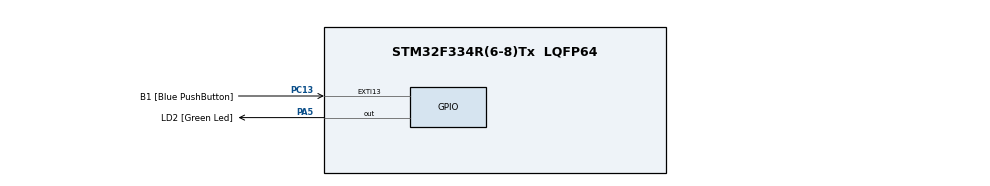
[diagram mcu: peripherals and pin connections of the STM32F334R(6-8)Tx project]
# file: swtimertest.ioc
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Mcu.Family=STM32F3
Mcu.Name=STM32F334R(6-8)Tx
Mcu.Package=LQFP64
Mcu.UserConstants=CLOCKS_PER_USEC,64;T7_COUNTS_PER_MSEC,1000;T3_NS_PER_COUNT,250;T3_COUNTS_PER_USEC,4;T3_MAX_USEC,16384;T3_MAX_MSEC,16;T7_COUNTS_PER_USEC,1;T7_NS_PER_COUNT,1000
NVIC.PriorityGroup=NVIC_PRIORITYGROUP_2
NVIC.TIM3_IRQn=true\:1\:1\:true\:true\:true\:2\:true
NVIC.TIM7_DAC2_IRQn=true\:1\:2\:true\:true\:true\:1\:true
PA13.GPIO_Label=TMS
PA13.Mode=Serial_Wire
PA13.Signal=SYS_JTMS-SWDIO
PA14.GPIO_Label=TCK
PA14.Mode=Serial_Wire
PA14.Signal=SYS_JTCK-SWCLK
PA2.GPIO_Label=USART_TX
PA2.Signal=USART2_TX
PA3.GPIO_Label=USART_RX
PA3.Signal=USART2_RX
PA5.GPIO_Label=LD2 [Green Led]
PA5.Signal=GPIO_Output
PB3.GPIO_Label=SWO
PB3.Signal=SYS_JTDO-TRACESWO
PC13.GPIO_Label=B1 [Blue PushButton]
PC13.GPIO_ModeDefaultEXTI=GPIO_MODE_IT_FALLING
PC13.Signal=GPXTI13
PC14\ /\ OSC32_IN.Signal=RCC_OSC32_IN
PC15\ /\ OSC32_OUT.GPIO_Label=RCC_OSC32_OUT
PC15\ /\ OSC32_OUT.Signal=RCC_OSC32_OUT
PF0\ /\ OSC_IN.Signal=RCC_OSC_IN
PF1\ /\ OSC_OUT.Signal=RCC_OSC_OUT
ProjectManager.HeapSize=0x200
ProjectManager.StackSize=0x1000
ProjectManager.TargetToolchain=MDK-ARM V5
RCC.AHBFreq_Value=64000000
RCC.APB1CLKDivider=RCC_HCLK_DIV2
RCC.APB1Freq_Value=32000000
RCC.APB1TimFreq_Value=64000000
RCC.APB2Freq_Value=64000000
RCC.APB2TimFreq_Value=64000000
RCC.CortexFreq_Value=64000000
RCC.FLatency-AdvancedSettings=FLASH_LATENCY_2
RCC.HCLKFreq_Value=64000000
RCC.HSE_VALUE=8000000
RCC.HSI_VALUE=8000000
RCC.LSE_VALUE=32768
RCC.PLLMUL=RCC_PLL_MUL16
RCC.SYSCLKFreq_VALUE=64000000
RCC.SYSCLKSourceVirtual=RCC_SYSCLKSOURCE_PLLCLK
TIM3.Channel-Output\ Compare1\ No\ Output=TIM_CHANNEL_1
TIM3.Channel-Output\ Compare2\ No\ Output=TIM_CHANNEL_2
TIM3.Channel-Output\ Compare3\ No\ Output=TIM_CHANNEL_3
TIM3.Channel-Output\ Compare4\ No\ Output=TIM_CHANNEL_4
TIM3.Period=0xffff
TIM3.Prescaler=15
TIM3.TIM_MasterSlaveMode=TIM_MASTERSLAVEMODE_ENABLE
TIM7.Period=65535
TIM7.Prescaler=63
VP_CRC_VS_CRC.Mode=CRC_Activate
VP_TIM3_VS_ClockSourceINT.Mode=Internal
VP_TIM3_VS_no_output1.Mode=Output Compare1 No Output
VP_TIM3_VS_no_output2.Mode=Output Compare2 No Output
VP_TIM3_VS_no_output3.Mode=Output Compare3 No Output
VP_TIM3_VS_no_output4.Mode=Output Compare4 No Output
VP_TIM7_VS_ClockSourceINT.Mode=Enable_Timer
board=NUCLEO-F334R8

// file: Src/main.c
/**
  ******************************************************************************
  * File Name          : main.c
  * Description        : Main program body
  ******************************************************************************
  ** This notice applies to any and all portions of this file
  * that are not between comment pairs USER CODE BEGIN and
  * USER CODE END. Other portions of this file, whether
  * inserted by the user or by software development tools
  * are owned by their respective copyright owners.
  *
  * COPYRIGHT(c) 2018 STMicroelectronics
  *
  * Redistribution and use in source and binary forms, with or without modification,
  * are permitted provided that the following conditions are met:
  *   1. Redistributions of source code must retain the above copyright notice,
  *      this list of conditions and the following disclaimer.
  *   2. Redistributions in binary form must reproduce the above copyright notice,
  *      this list of conditions and the following disclaimer in the documentation
  *      and/or other materials provided with the distribution.
  *   3. Neither the name of STMicroelectronics nor the names of its contributors
  *      may be used to endorse or promote products derived from this software
  *      without specific prior written permission.
  *
  * THIS SOFTWARE IS PROVIDED BY THE COPYRIGHT HOLDERS AND CONTRIBUTORS "AS IS"
  * AND ANY EXPRESS OR IMPLIED WARRANTIES, INCLUDING, BUT NOT LIMITED TO, THE
  * IMPLIED WARRANTIES OF MERCHANTABILITY AND FITNESS FOR A PARTICULAR PURPOSE ARE
  * DISCLAIMED. IN NO EVENT SHALL THE COPYRIGHT HOLDER OR CONTRIBUTORS BE LIABLE
  * FOR ANY DIRECT, INDIRECT, INCIDENTAL, SPECIAL, EXEMPLARY, OR CONSEQUENTIAL
  * DAMAGES (INCLUDING, BUT NOT LIMITED TO, PROCUREMENT OF SUBSTITUTE GOODS OR
  * SERVICES; LOSS OF USE, DATA, OR PROFITS; OR BUSINESS INTERRUPTION) HOWEVER
  * CAUSED AND ON ANY THEORY OF LIABILITY, WHETHER IN CONTRACT, STRICT LIABILITY,
  * OR TORT (INCLUDING NEGLIGENCE OR OTHERWISE) ARISING IN ANY WAY OUT OF THE USE
  * OF THIS SOFTWARE, EVEN IF ADVISED OF THE POSSIBILITY OF SUCH DAMAGE.
  *
  ******************************************************************************
  */
#include "main.h"
#include "stm32f3xx_hal.h"
#include "crc.h"
#include "tim.h"
#include "gpio.h"

/* USER CODE BEGIN Includes */
#include <alloca.h>
#include "taskService.h"
#include "swbgtimers.h"
#include "gencmdef.h"
#include "generalQueue.h"

/* USER CODE END Includes */

/* USER CODE BEGIN PV */
/* Private variables ---------------------------------------------------------*/

/* USER CODE END PV */

void SystemClock_Config(void);
static void MX_NVIC_Init(void);

/* USER CODE BEGIN PFP */
/* Private function prototypes -----------------------------------------------*/

/* USER CODE END PFP */

/* USER CODE BEGIN 0 */
#define NUM_OF_TASKS 10
extern __IO uint32_t uwTick;
__IO uint32_t *someCounter = &uwTick;

uint32_t tasksAllowed;
taskHandle_t bgTimerTask;
taskHandle_t task1Task;
taskHandle_t task2Task;
taskHandle_t task3Task;
taskHandle_t task4Task;
uint32_t GetTimeuSec(void);
uint32_t extendedTick;
uint32_t testusec;
/// The system tick callback
void HAL_SYSTICK_Callback(void)
{
    // Schedule background timer task
    TS_SignalTask(bgTimerTask);
    if (uwTick == 0)extendedTick++;
    testusec = GetTimeuSec();
}

volatile uint32_t Clock3;
volatile uint32_t Clock7;

/// The timer rollover ISR callback
void HAL_TIM_PeriodElapsedCallback(TIM_HandleTypeDef *htim)
{
    if (htim == &htim3) ++Clock3;
    if (htim == &htim7) ++Clock7;
}

uint32_t GetTimeuSec(void)
{
    uint32_t change, time1 = (Clock3<<14)+ ((htim3.Instance->CNT)>>2);
    uint32_t time2;
    do
    {
        time2 = (Clock3<<14)+ ((htim3.Instance->CNT)>>2);
        if (time2 - time1 > 1)
        {
            time1=time2;
            change=1;
        }
        else change = 0;
    }while(change);

    return time2;
}

static void subTask(int cnt)
{
    volatile int i;
    for (i = 0; i < cnt; i++)
    {
        if ( 0 == i%1000 )
        {
            TS_Yield();
        }
    }
}

void task1(void)
{
    subTask(3000);
    TS_SignalTask(task4Task);
    TS_SignalTask(task2Task);
}

void task2(void)
{
    subTask(30000);
    TS_SignalTask(task3Task);
}

void task3(void)
{
    subTask(300000);
    TS_SignalTask(task1Task);
}

void task4(void)
{
    subTask(3000000);
    TS_SignalTask(task2Task);
}

uint32_t futureCalled;

int32_t fut2dif;
void futureTest2(intptr_t startTime)
{
    static int32_t cnt;
    futureCalled++;
    fut2dif = (GetTimeuSec() - startTime) / ++cnt;
}

int32_t fut20dif;
void futureTest20(intptr_t startTime)
{
    static int32_t cnt;
    futureCalled++;
    fut20dif = (GetTimeuSec() - startTime) / ++cnt;
}

int32_t fut200dif;
void futureTest200(intptr_t startTime)
{
    static int32_t cnt;
    futureCalled++;
    fut200dif = (GetTimeuSec() - startTime) / ++cnt;
}

int32_t fut2000dif;
void futureTest2000(intptr_t startTime)
{
    static int32_t cnt;
    futureCalled++;
    fut2000dif = (GetTimeuSec() - startTime) / ++cnt;
}

/* USER CODE END 0 */

int main(void)
{

  /* MCU Configuration----------------------------------------------------------*/

  /* Reset of all peripherals, Initializes the Flash interface and the Systick. */
  HAL_Init();

  /* Configure the system clock */
  SystemClock_Config();

  /* Initialize all configured peripherals */
  MX_GPIO_Init();
  MX_TIM7_Init();
  MX_CRC_Init();
  MX_TIM3_Init();

  /* Initialize interrupts */
  MX_NVIC_Init();

  /* USER CODE BEGIN 2 */

  HAL_ResumeTick();

  HAL_TIM_Base_Start_IT(&htim3);
//  HAL_TIM_Base_Start_IT(&htim6);
  HAL_TIM_Base_Start_IT(&htim7);

  SWT_FastInit();

  // allocate space for the tasks
  uint32_t *space = alloca(TS_InitGetSize(NUM_OF_TASKS));
  tasksAllowed = TS_Init(space,TS_InitGetSize(NUM_OF_TASKS));
  if(tasksAllowed != NUM_OF_TASKS)
    { while (1) {} }  // Oh Crap
  // make the background timer a task itself
  bgTimerTask =  TS_AddTask(SWT_Background);
  task1Task =  TS_AddTask(task1);
  task2Task =  TS_AddTask(task2);
  task3Task =  TS_AddTask(task3);
  task4Task =  TS_AddTask(task4);

  TS_SignalTask(task3Task);

  // launch future test
SWT_FastTimerCallback(futureTest2000, 2000000, 256, GetTimeuSec());
SWT_FastTimerCallback(futureTest200, 200000, 256, GetTimeuSec());
SWT_FastTimerCallback(futureTest20, 20000, 256, GetTimeuSec());
SWT_FastTimerCallback(futureTest2, 2000, 256, GetTimeuSec());

  /* USER CODE END 2 */

  /* Infinite loop */
  /* USER CODE BEGIN WHILE */
  while (1)
  {
    // The task runner
    TS_Background();
  /* USER CODE END WHILE */

  }

}

/** System Clock Configuration
*/
void SystemClock_Config(void)
{

  LL_FLASH_SetLatency(LL_FLASH_LATENCY_2);

   if(LL_FLASH_GetLatency() != LL_FLASH_LATENCY_2)
  {
  Error_Handler();
  }
  LL_RCC_HSI_Enable();

   /* Wait till HSI is ready */
  while(LL_RCC_HSI_IsReady() != 1)
  {

  }
  LL_RCC_HSI_SetCalibTrimming(16);

  LL_RCC_PLL_ConfigDomain_SYS(LL_RCC_PLLSOURCE_HSI_DIV_2, LL_RCC_PLL_MUL_16);

  LL_RCC_PLL_Enable();

   /* Wait till PLL is ready */
  while(LL_RCC_PLL_IsReady() != 1)
  {

  }
  LL_RCC_SetAHBPrescaler(LL_RCC_SYSCLK_DIV_1);

  LL_RCC_SetAPB1Prescaler(LL_RCC_APB1_DIV_2);

  LL_RCC_SetAPB2Prescaler(LL_RCC_APB1_DIV_1);

  LL_RCC_SetSysClkSource(LL_RCC_SYS_CLKSOURCE_PLL);

   /* Wait till System clock is ready */
  while(LL_RCC_GetSysClkSource() != LL_RCC_SYS_CLKSOURCE_STATUS_PLL)
  {

  }
  LL_Init1msTick(64000000);

  LL_SYSTICK_SetClkSource(LL_SYSTICK_CLKSOURCE_HCLK);

  LL_SetSystemCoreClock(64000000);

  /* SysTick_IRQn interrupt configuration */
  NVIC_SetPriority(SysTick_IRQn, NVIC_EncodePriority(NVIC_GetPriorityGrouping(),0, 0));
}

/** NVIC Configuration
*/
static void MX_NVIC_Init(void)
{
  /* TIM7_DAC2_IRQn interrupt configuration */
  HAL_NVIC_SetPriority(TIM7_DAC2_IRQn, 1, 2);
  HAL_NVIC_EnableIRQ(TIM7_DAC2_IRQn);
  /* TIM3_IRQn interrupt configuration */
  HAL_NVIC_SetPriority(TIM3_IRQn, 1, 1);
  HAL_NVIC_EnableIRQ(TIM3_IRQn);
}

void _Error_Handler(char * file, int line)
{
  while(1)
  {
  }
}

/************************ (C) COPYRIGHT STMicroelectronics *****END OF FILE****/
